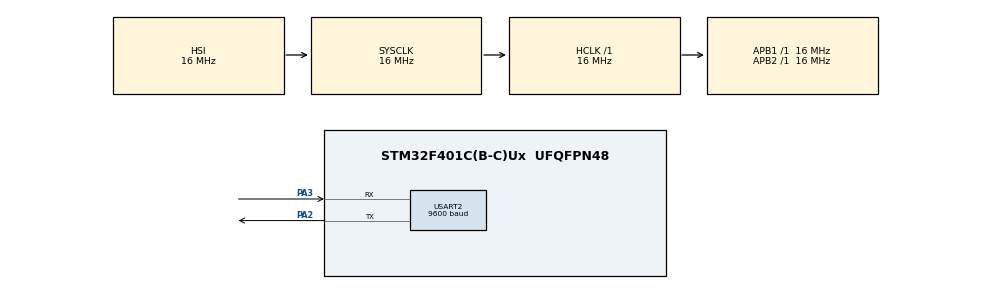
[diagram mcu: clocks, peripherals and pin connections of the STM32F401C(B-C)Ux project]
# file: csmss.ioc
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FREERTOS.BinarySemaphores01=gps_semaphore,Static,gps_semaphoreControlBlock;UART2_semaphore,Static,UART2_semaphoreControlBlock
FREERTOS.Tasks01=defaultTask,24,128,StartDefaultTask,Default,NULL,Dynamic,NULL,NULL;Recieve_uart,16,128,StartTask02,Default,NULL,Static,Recieve_uartBuffer,Recieve_uartControlBlock
Mcu.Family=STM32F4
Mcu.Name=STM32F401C(B-C)Ux
Mcu.Package=UFQFPN48
NVIC.PriorityGroup=NVIC_PRIORITYGROUP_4
NVIC.RCC_IRQn=true\:5\:0\:false\:false\:true\:true\:true\:false\:true
PA2.Mode=Asynchronous
PA2.Signal=USART2_TX
PA3.Mode=Asynchronous
PA3.Signal=USART2_RX
ProjectManager.HeapSize=0x200
ProjectManager.StackSize=0x400
ProjectManager.TargetToolchain=STM32CubeIDE
RCC.AHBFreq_Value=16000000
RCC.APB1Freq_Value=16000000
RCC.APB2Freq_Value=16000000
RCC.CortexFreq_Value=16000000
RCC.HSE_VALUE=25000000
RCC.HSI_VALUE=16000000
RCC.LSE_VALUE=32768
RCC.SYSCLKFreq_VALUE=16000000
RCC.VCOOutputFreq_Value=192000000
USART2.BaudRate=9600
USART2.VirtualMode=VM_ASYNC
VP_FREERTOS_VS_CMSIS_V2.Mode=CMSIS_V2
board=custom

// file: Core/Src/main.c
/* USER CODE BEGIN Header */
/**
  ******************************************************************************
  * @file           : main.c
  * @brief          : Main program body
  ******************************************************************************
  * @attention
  *
  * Copyright (c) 2024 STMicroelectronics.
  * All rights reserved.
  *
  * This software is licensed under terms that can be found in the LICENSE file
  * in the root directory of this software component.
  * If no LICENSE file comes with this software, it is provided AS-IS.
  *
  ******************************************************************************
  */
/* USER CODE END Header */
#include "main.h"
#include "gps.h"
#include "cmsis_os.h"

typedef StaticTask_t osStaticThreadDef_t;
typedef StaticSemaphore_t osStaticSemaphoreDef_t;

UART_HandleTypeDef huart2;

/* Definitions for defaultTask */
osThreadId_t defaultTaskHandle;
const osThreadAttr_t defaultTask_attributes = {
  .name = "defaultTask",
  .stack_size = 128 * 4,
  .priority = (osPriority_t) osPriorityNormal,
};
/* Definitions for Recieve_uart */
osThreadId_t Recieve_uartHandle;
uint32_t Recieve_uartBuffer[ 128 ];
osStaticThreadDef_t Recieve_uartControlBlock;
const osThreadAttr_t Recieve_uart_attributes = {
  .name = "Recieve_uart",
  .cb_mem = &Recieve_uartControlBlock,
  .cb_size = sizeof(Recieve_uartControlBlock),
  .stack_mem = &Recieve_uartBuffer[0],
  .stack_size = sizeof(Recieve_uartBuffer),
  .priority = (osPriority_t) osPriorityBelowNormal,
};
/* Definitions for gps_semaphore */
osSemaphoreId_t gps_semaphoreHandle;
osStaticSemaphoreDef_t gps_semaphoreControlBlock;
const osSemaphoreAttr_t gps_semaphore_attributes = {
  .name = "gps_semaphore",
  .cb_mem = &gps_semaphoreControlBlock,
  .cb_size = sizeof(gps_semaphoreControlBlock),
};
/* Definitions for UART2_semaphore */
osSemaphoreId_t UART2_semaphoreHandle;
osStaticSemaphoreDef_t UART2_semaphoreControlBlock;
const osSemaphoreAttr_t UART2_semaphore_attributes = {
  .name = "UART2_semaphore",
  .cb_mem = &UART2_semaphoreControlBlock,
  .cb_size = sizeof(UART2_semaphoreControlBlock),
};

void SystemClock_Config(void);
static void MX_GPIO_Init(void);
static void MX_USART2_UART_Init(void);
void StartDefaultTask(void *argument);
void StartTask02(void *argument);
extern unsigned char rx_data;
extern unsigned char rx_buffer[GPSBUFSIZE];
extern unsigned char rx_index;

int main(void)
{

  /* MCU Configuration--------------------------------------------------------*/

  /* Reset of all peripherals, Initializes the Flash interface and the Systick. */
  HAL_Init();

  /* Configure the system clock */
  SystemClock_Config();

  /* Initialize all configured peripherals */
  MX_GPIO_Init();
  MX_USART2_UART_Init();
  /* USER CODE BEGIN 2 */
  GPS_Init();
  /* USER CODE END 2 */

  /* Init scheduler */
  osKernelInitialize();

  /* Create the semaphores(s) */
  /* creation of gps_semaphore */
  gps_semaphoreHandle = osSemaphoreNew(1, 0, &gps_semaphore_attributes);

  /* creation of UART2_semaphore */
  UART2_semaphoreHandle = osSemaphoreNew(1, 0, &UART2_semaphore_attributes);

  /* Create the thread(s) */
  /* creation of defaultTask */
  defaultTaskHandle = osThreadNew(StartDefaultTask, NULL, &defaultTask_attributes);

  /* creation of Recieve_uart */
  Recieve_uartHandle = osThreadNew(StartTask02, NULL, &Recieve_uart_attributes);

  /* Start scheduler */
  osKernelStart();

  /* We should never get here as control is now taken by the scheduler */
  /* Infinite loop */
  while (1)
  {

  }
}

void SystemClock_Config(void)
{
  RCC_OscInitTypeDef RCC_OscInitStruct = {0};
  RCC_ClkInitTypeDef RCC_ClkInitStruct = {0};

  /** Configure the main internal regulator output voltage
  */
  __HAL_RCC_PWR_CLK_ENABLE();
  __HAL_PWR_VOLTAGESCALING_CONFIG(PWR_REGULATOR_VOLTAGE_SCALE2);

  /** Initializes the RCC Oscillators according to the specified parameters
  * in the RCC_OscInitTypeDef structure.
  */
  RCC_OscInitStruct.OscillatorType = RCC_OSCILLATORTYPE_HSI;
  RCC_OscInitStruct.HSIState = RCC_HSI_ON;
  RCC_OscInitStruct.HSICalibrationValue = RCC_HSICALIBRATION_DEFAULT;
  RCC_OscInitStruct.PLL.PLLState = RCC_PLL_NONE;
  if (HAL_RCC_OscConfig(&RCC_OscInitStruct) != HAL_OK)
  {
    Error_Handler();
  }

  /** Initializes the CPU, AHB and APB buses clocks
  */
  RCC_ClkInitStruct.ClockType = RCC_CLOCKTYPE_HCLK|RCC_CLOCKTYPE_SYSCLK
                              |RCC_CLOCKTYPE_PCLK1|RCC_CLOCKTYPE_PCLK2;
  RCC_ClkInitStruct.SYSCLKSource = RCC_SYSCLKSOURCE_HSI;
  RCC_ClkInitStruct.AHBCLKDivider = RCC_SYSCLK_DIV1;
  RCC_ClkInitStruct.APB1CLKDivider = RCC_HCLK_DIV1;
  RCC_ClkInitStruct.APB2CLKDivider = RCC_HCLK_DIV1;

  if (HAL_RCC_ClockConfig(&RCC_ClkInitStruct, FLASH_LATENCY_0) != HAL_OK)
  {
    Error_Handler();
  }
}

static void MX_USART2_UART_Init(void)
{

  huart2.Instance = USART2;
  huart2.Init.BaudRate = 9600;
  huart2.Init.WordLength = UART_WORDLENGTH_8B;
  huart2.Init.StopBits = UART_STOPBITS_1;
  huart2.Init.Parity = UART_PARITY_NONE;
  huart2.Init.Mode = UART_MODE_TX_RX;
  huart2.Init.HwFlowCtl = UART_HWCONTROL_NONE;
  huart2.Init.OverSampling = UART_OVERSAMPLING_16;
  if (HAL_UART_Init(&huart2) != HAL_OK)
  {
    Error_Handler();
  }

}

static void MX_GPIO_Init(void)
{

  /* GPIO Ports Clock Enable */
  __HAL_RCC_GPIOA_CLK_ENABLE();

}

void StartDefaultTask(void *argument)
{
  for(;;)
  {
    osDelay(1);
  }
}

void StartTask02(void *argument)
{
  /* USER CODE BEGIN StartTask02 */
  /* Infinite loop */
	GPS_Recieve();
	vTaskDelay(pdMS_TO_TICKS(1000)); // Delay for 1000 ms (1 second)
//    for(;;)
//    {
//      osDelay(1);
//    }
  /* USER CODE END StartTask02 */
}

void Error_Handler(void)
{
  __disable_irq();
  while (1)
  {
  }
}
